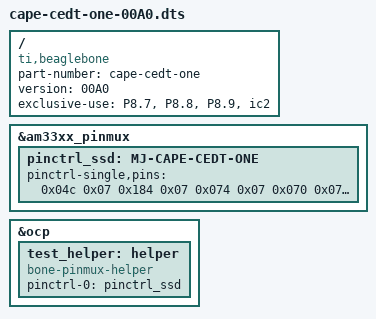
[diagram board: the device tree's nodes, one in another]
/*
 * Copyright (C) 2012 Texas Instruments Incorporated - http://www.ti.com/
 *
 * This program is free software; you can redistribute it and/or modify
 * it under the terms of the GNU General Public License version 2 as
 * published by the Free Software Foundation.
 * Original from: github.com/jadonk/validation-scripts/blob/master/test-capemgr/ 
 * 
 * Modified by Mrityunjai Kumar <www.mrityunjai.in> 
 * Modified for cape One 
 *
 */

/dts-v1/;
/plugin/;

/{
 	compatible = "ti,beaglebone", "ti,beaglebone-black";

	/*Identification*/
 	part-number = "cape-cedt-one";
 	version = "00A0";

	/* state the resources this cape uses */
	exclusive-use =
 		"P8.7", /*change these values*/
        	"P8.8",
        	"P8.9",
		"ic2";
	
	fragment@0 {
        	target = <&am33xx_pinmux>;
	    	__overlay__ {
	    	pinctrl_ssd: MJ-CAPE-CEDT-ONE {
				pinctrl-single,pins = 	<
		    									0x04c	0x07	//SSD_a		P9_16	gpio1[19] 	51
											0x184	0x07	//SSD_b		P9_24	gpio0[15]	15
											0x074	0x07	//SSD_c		P9_13	gpio0[31] 	31
											0x070	0x07	//SSD_d		P9_11	gpio0[30] 	30
											0x078	0x07	//SSD_e		P9_12	gpio1[28] 	60
											0x048	0x07	//SSD_f		P9_14	gpio1[18] 	50
											0x040	0x07	//SSD_g		P9_15	gpio1[16] 	48
											0x15c	0x07	//SSD_.		P9_17	gpio0[5] 	5
											0x158	0x07	//SSD_d1	P9_18	gpio0[4] 	4
											0x044	0x07	//SSD_d2	P9_23	 gpio1[17]	49
											0x180	0x07	//SSD_d3	P9_26	Gpio0[14]	96
											0x154	0x07	//SSD_d4	P9_21	gpio0[3] 	3
											//0x164	0x07	//buzzer	P9_42	 gpio0[7]	89					Output	muxed with LED	15
											0x1a4	0x2f	//push_button1	P9_27	Gpio3[19]	115	1	0	1	111	input		16
											0x1ac	0x2f	//push_button2	P9_25	Gpio3[21]	117	1	0	1	111	input		17
											//0x164	0x00	// led 		P9_42	ECAPPWM0						Output	muxed with LED	15

											
										>;
		  									};
             			};
       			};

fragment@1 {
        target = <&ocp>;
        __overlay__ {
            test_helper: helper {
                compatible = "bone-pinmux-helper";
                pinctrl-names = "default";
                pinctrl-0 = <&pinctrl_ssd>;
                status = "okay";
            };
        };
    };

};
